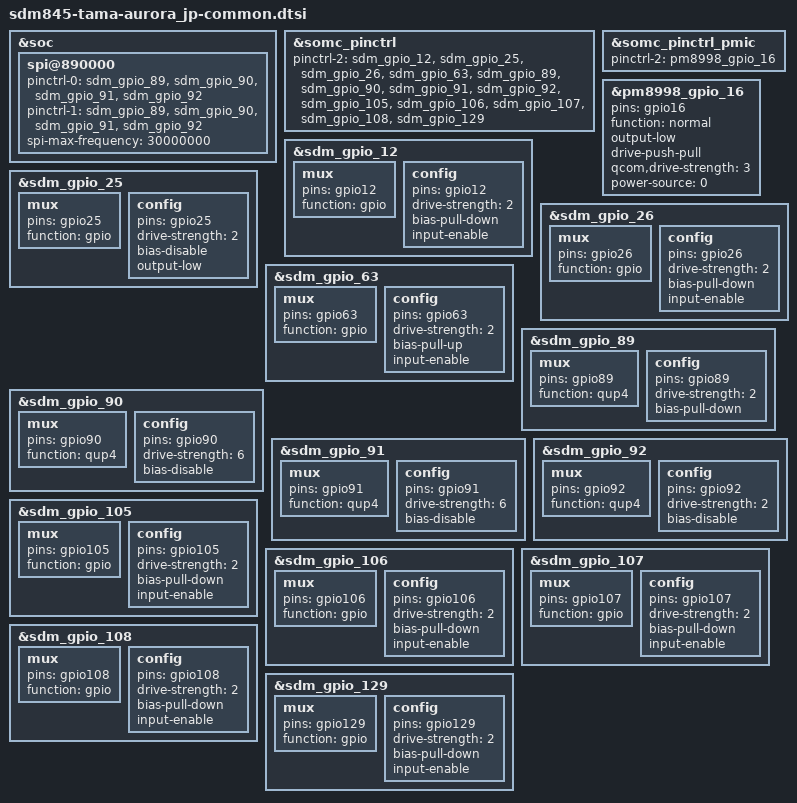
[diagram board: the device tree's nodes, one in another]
/* arch/arm64/boot/dts/somc/sdm845-tama-aurora_jp-common.dtsi
 *
 * This program is free software; you can redistribute it and/or modify
 * it under the terms of the GNU General Public License version 2 and
 * only version 2 as published by the Free Software Foundation.
 *
 * This program is distributed in the hope that it will be useful,
 * but WITHOUT ANY WARRANTY; without even the implied warranty of
 * MERCHANTABILITY or FITNESS FOR A PARTICULAR PURPOSE.  See the
 * GNU General Public License for more details.
 */
/*
 * Copyright (C) 2017 Sony Mobile Communications Inc.
 *
 * This program is free software; you can redistribute it and/or modify
 * it under the terms of the GNU General Public License version 2, as
 * published by the Free Software Foundation.
 */

#include "sdm845-tama-aurora_common.dtsi"

&soc {
	/* SPI: QUP4 */
	spi@890000 {
		pinctrl-0 = <&sdm_gpio_89 &sdm_gpio_90 &sdm_gpio_91 &sdm_gpio_92>;
		pinctrl-1 = <&sdm_gpio_89 &sdm_gpio_90 &sdm_gpio_91 &sdm_gpio_92>;
		spi-max-frequency = <30000000>;
		status = "okay";
	};
};

&somc_pinctrl {
	pinctrl-2 = <&sdm_gpio_12 &sdm_gpio_25 &sdm_gpio_26 &sdm_gpio_63 &sdm_gpio_89
		     &sdm_gpio_90 &sdm_gpio_91 &sdm_gpio_92 &sdm_gpio_105 &sdm_gpio_106
		     &sdm_gpio_107 &sdm_gpio_108 &sdm_gpio_129>;
};

&somc_pinctrl_pmic {
	pinctrl-2 = <&pm8998_gpio_16>;
};

/* GPIO_16: DTV_PWR_EN */
&pm8998_gpio_16 {
	pins = "gpio16";
	/delete-property/ bias-high-impedance;
	function = "normal";
	output-low;
	drive-push-pull;
	qcom,drive-strength = <3>;
	power-source = <0>;
};

/* GPIO_12: NC */
&sdm_gpio_12 {
	mux {
		pins = "gpio12";
		function = "gpio";
	};

	config {
		pins = "gpio12";
		drive-strength = <2>;
		/delete-property/ bias-disable;
		bias-pull-down;
		/delete-property/ output-low;
		input-enable;
	};
};

/* GPIO_25: DTV_RST_N */
&sdm_gpio_25 {
	mux {
		pins = "gpio25";
		function = "gpio";
	};

	config {
		pins = "gpio25";
		drive-strength = <2>;
		/delete-property/ bias-pull-down;
		bias-disable;
		/delete-property/ input-enable;
		output-low;
	};
};

/* GPIO_26: DTV_INT */
&sdm_gpio_26 {
	mux {
		pins = "gpio26";
		function = "gpio";
	};

	config {
		pins = "gpio26";
		drive-strength = <2>;
		bias-pull-down;
		input-enable;
	};
};

/* GPIO_63: FELICA_INT_N */
&sdm_gpio_63 {
	mux {
		pins = "gpio63";
		function = "gpio";
	};

	config {
		pins = "gpio63";
		drive-strength = <2>;
		/delete-property/ bias-pull-down;
		bias-pull-up;
		input-enable;
	};
};

/* GPIO_89: DTV_SPI_MISO */
&sdm_gpio_89 {
	mux {
		pins = "gpio89";
		function = "qup4";
	};

	config {
		pins = "gpio89";
		drive-strength = <2>;
		bias-pull-down;
		/delete-property/ input-enable;
	};
};

/* GPIO_90: DTV_SPI_MOSI */
&sdm_gpio_90 {
	mux {
		pins = "gpio90";
		function = "qup4";
	};

	config {
		pins = "gpio90";
		drive-strength = <6>;
		/delete-property/ bias-pull-down;
		bias-disable;
		/delete-property/ input-enable;
	};
};

/* GPIO_91: DTV_SPI_CLK */
&sdm_gpio_91 {
	mux {
		pins = "gpio91";
		function = "qup4";
	};

	config {
		pins = "gpio91";
		drive-strength = <6>;
		/delete-property/ bias-pull-down;
		bias-disable;
		/delete-property/ input-enable;
	};
};

/* GPIO_92: DTV_SPI_CS_N */
&sdm_gpio_92 {
	mux {
		pins = "gpio92";
		function = "qup4";
	};

	config {
		pins = "gpio92";
		drive-strength = <2>;
		/delete-property/ bias-pull-down;
		bias-disable;
		/delete-property/ input-enable;
	};
};

/* GPIO_105: NC */
&sdm_gpio_105 {
	mux {
		pins = "gpio105";
		function = "gpio";
	};

	config {
		pins = "gpio105";
		drive-strength = <2>;
		bias-pull-down;
		input-enable;
	};
};

/* GPIO_106: NC */
&sdm_gpio_106 {
	mux {
		pins = "gpio106";
		function = "gpio";
	};

	config {
		pins = "gpio106";
		drive-strength = <2>;
		bias-pull-down;
		input-enable;
	};
};

/* GPIO_107: NC */
&sdm_gpio_107 {
	mux {
		pins = "gpio107";
		function = "gpio";
	};

	config {
		pins = "gpio107";
		drive-strength = <2>;
		bias-pull-down;
		input-enable;
	};
};

/* GPIO_108: NC */
&sdm_gpio_108 {
	mux {
		pins = "gpio108";
		function = "gpio";
	};

	config {
		pins = "gpio108";
		drive-strength = <2>;
		/delete-property/ bias-disable;
		bias-pull-down;
		input-enable;
	};
};

/* GPIO_129: NC */
&sdm_gpio_129 {
	mux {
		pins = "gpio129";
		function = "gpio";
	};

	config {
		pins = "gpio129";
		drive-strength = <2>;
		/delete-property/ bias-disable;
		bias-pull-down;
		/delete-property/ output-low;
		input-enable;
	};
};
